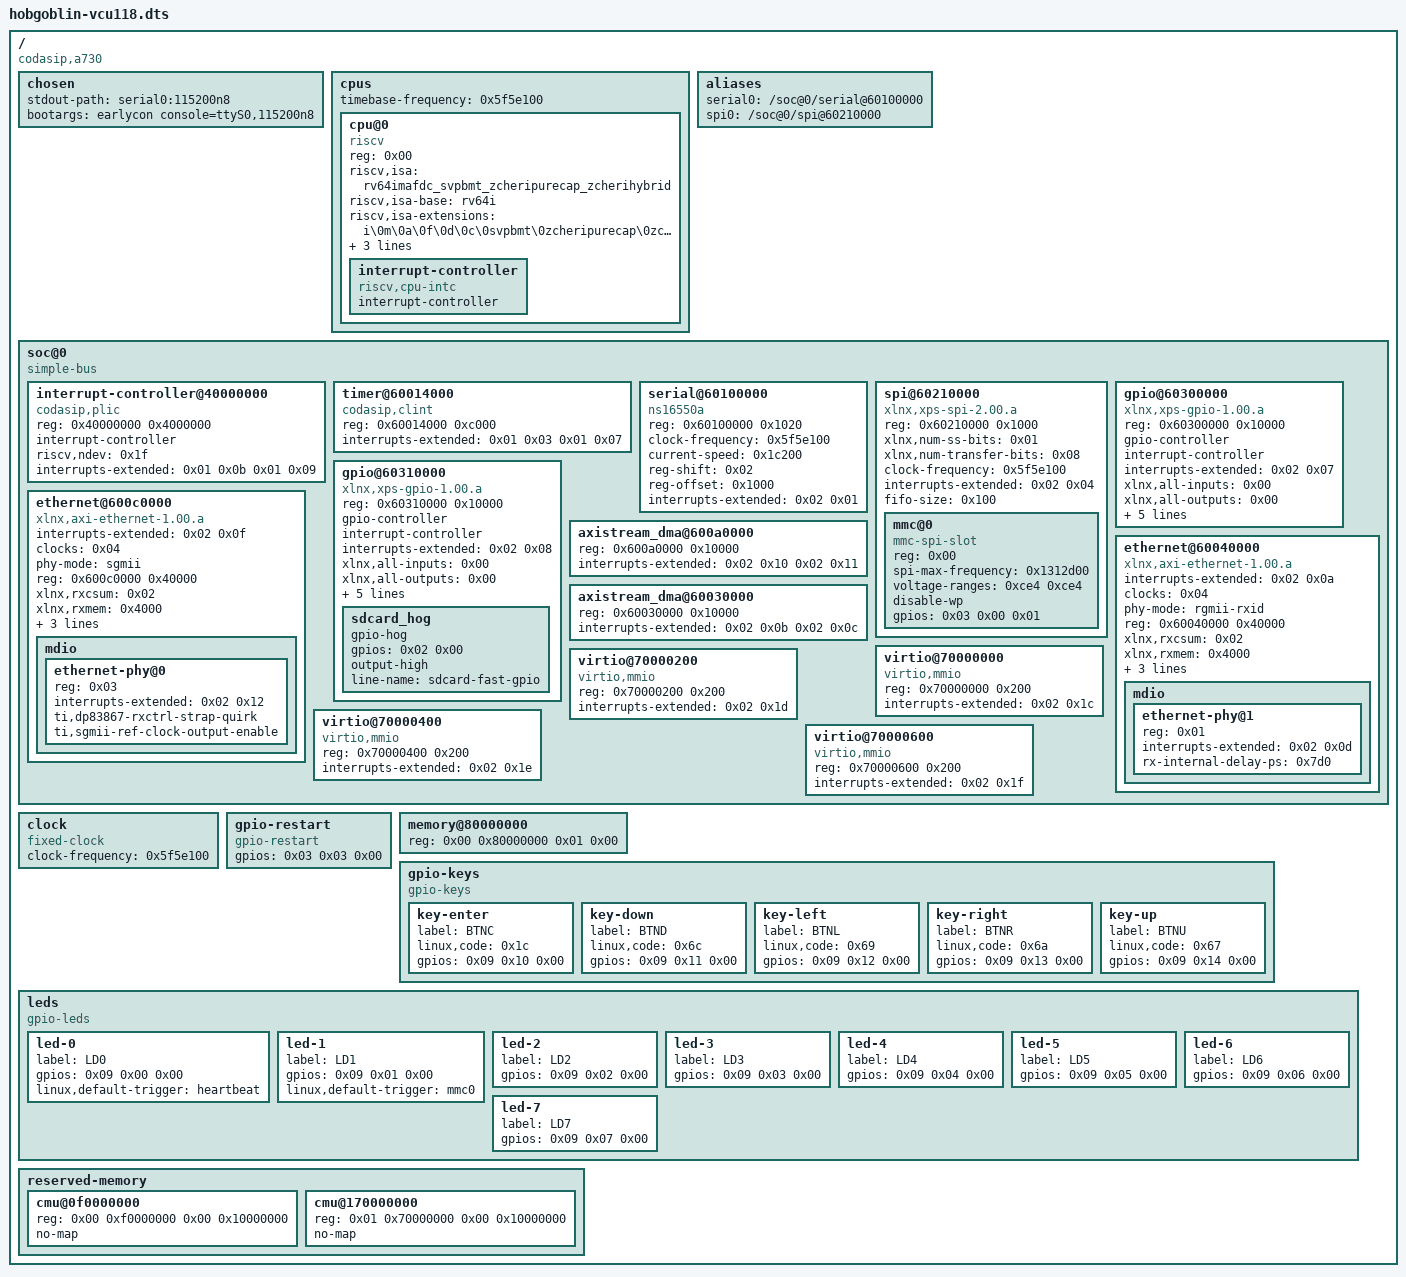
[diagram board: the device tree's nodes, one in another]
/*
 * Copyright (c) 2025, Capabilities Ltd <heshamalmatary@capabilitieslimited.co.uk>
 * This file was derived from Codasip's tools.
 * SPDX-License-Identifier: BSD-3-Clause
 */
/dts-v1/;

/ {
	#address-cells = <0x02>;
	#size-cells = <0x02>;
	compatible = "codasip,a730";

	chosen {
		stdout-path = "serial0:115200n8";
		bootargs = "earlycon console=ttyS0,115200n8";
	};

	cpus {
		#address-cells = <0x01>;
		#size-cells = <0x00>;
		timebase-frequency = <0x5f5e100>;

		cpu@0 {
			compatible = "riscv";
			device_type = "cpu";
			reg = <0x00>;
			riscv,isa = "rv64imafdc_svpbmt_zcheripurecap_zcherihybrid";
			riscv,isa-base = "rv64i";
			riscv,isa-extensions = "i\0m\0a\0f\0d\0c\0svpbmt\0zcheripurecap\0zcherihybrid";
			riscv,cbom-block-size = <0x40>;
			riscv,cboz-block-size = <0x40>;
			mmu-type = "riscv,sv39";
			status = "okay";

			interrupt-controller {
				#interrupt-cells = <0x01>;
				#address-cells = <0x00>;
				compatible = "riscv,cpu-intc";
				interrupt-controller;
				status = "okay";
				phandle = <0x01>;
			};
		};
	};

	aliases {
		serial0 = "/soc@0/serial@60100000";
		spi0 = "/soc@0/spi@60210000";
	};

	soc@0 {
		#address-cells = <0x01>;
		#size-cells = <0x01>;
		compatible = "simple-bus";
		ranges = <0x00 0x00 0x00 0x80000000>;

		interrupt-controller@40000000 {
			compatible = "codasip,plic\0sifive,plic-1.0.0\0riscv,plic0";
			reg = <0x40000000 0x4000000>;
			#address-cells = <0x00>;
			interrupt-controller;
			#interrupt-cells = <0x01>;
			riscv,ndev = <0x1f>;
			interrupts-extended = <0x01 0x0b 0x01 0x09>;
			phandle = <0x02>;
		};

		timer@60014000 {
			compatible = "codasip,clint\0sifive,clint0\0riscv,clint0";
			reg = <0x60014000 0xc000>;
			interrupts-extended = <0x01 0x03 0x01 0x07>;
		};

		serial@60100000 {
			compatible = "ns16550a";
			reg = <0x60100000 0x1020>;
			clock-frequency = <0x5f5e100>;
			current-speed = <0x1c200>;
			reg-shift = <0x02>;
			reg-offset = <0x1000>;
			interrupts-extended = <0x02 0x01>;
		};

		spi@60210000 {
			compatible = "xlnx,xps-spi-2.00.a";
			reg = <0x60210000 0x1000>;
			xlnx,num-ss-bits = <0x01>;
			xlnx,num-transfer-bits = <0x08>;
			clock-frequency = <0x5f5e100>;
			interrupts-extended = <0x02 0x04>;
			fifo-size = <0x100>;
			#address-cells = <0x01>;
			#size-cells = <0x00>;

			mmc@0 {
				compatible = "mmc-spi-slot";
				reg = <0x00>;
				spi-max-frequency = <0x1312d00>;
				voltage-ranges = <0xce4 0xce4>;
				disable-wp;
				gpios = <0x03 0x00 0x01>;
			};
		};

		gpio@60300000 {
			compatible = "xlnx,xps-gpio-1.00.a";
			reg = <0x60300000 0x10000>;
			#gpio-cells = <0x02>;
			#interrupt-cells = <0x02>;
			#address-cells = <0x00>;
			gpio-controller;
			interrupt-controller;
			interrupts-extended = <0x02 0x07>;
			xlnx,all-inputs = <0x00>;
			xlnx,all-outputs = <0x00>;
			xlnx,dout-default = <0x00>;
			xlnx,gpio-width = <0x20>;
			xlnx,interrupt-present = <0x01>;
			xlnx,is-dual = <0x00>;
			xlnx,tri-default = <0xfe>;
			phandle = <0x09>;
		};

		gpio@60310000 {
			compatible = "xlnx,xps-gpio-1.00.a";
			reg = <0x60310000 0x10000>;
			#gpio-cells = <0x02>;
			#interrupt-cells = <0x02>;
			#address-cells = <0x00>;
			gpio-controller;
			interrupt-controller;
			interrupts-extended = <0x02 0x08>;
			xlnx,all-inputs = <0x00>;
			xlnx,all-outputs = <0x00>;
			xlnx,dout-default = <0x00>;
			xlnx,gpio-width = <0x20>;
			xlnx,interrupt-present = <0x01>;
			xlnx,is-dual = <0x00>;
			xlnx,tri-default = <0x01>;
			phandle = <0x03>;

			sdcard_hog {
				gpio-hog;
				gpios = <0x02 0x00>;
				output-high;
				line-name = "sdcard-fast-gpio";
			};
		};

		ethernet@600c0000 {
			compatible = "xlnx,axi-ethernet-1.00.a";
			interrupts-extended = <0x02 0x0f>;
			clock-names = "s_axi_lite_clk";
			clocks = <0x04>;
			phy-mode = "sgmii";
			reg = <0x600c0000 0x40000>;
			xlnx,rxcsum = <0x02>;
			xlnx,rxmem = <0x4000>;
			xlnx,txcsum = <0x02>;
			phy-handle = <0x05>;
			axistream-connected = <0x06>;

			mdio {
				#address-cells = <0x01>;
				#size-cells = <0x00>;

				ethernet-phy@0 {
					device_type = "ethernet-phy";
					reg = <0x03>;
					interrupts-extended = <0x02 0x12>;
					ti,dp83867-rxctrl-strap-quirk;
					ti,sgmii-ref-clock-output-enable;
					phandle = <0x05>;
				};
			};
		};

		axistream_dma@600a0000 {
			reg = <0x600a0000 0x10000>;
			interrupts-extended = <0x02 0x10 0x02 0x11>;
			phandle = <0x06>;
		};

		ethernet@60040000 {
			compatible = "xlnx,axi-ethernet-1.00.a";
			interrupts-extended = <0x02 0x0a>;
			clock-names = "s_axi_lite_clk";
			clocks = <0x04>;
			phy-mode = "rgmii-rxid";
			reg = <0x60040000 0x40000>;
			xlnx,rxcsum = <0x02>;
			xlnx,rxmem = <0x4000>;
			xlnx,txcsum = <0x02>;
			phy-handle = <0x07>;
			axistream-connected = <0x08>;

			mdio {
				#address-cells = <0x01>;
				#size-cells = <0x00>;

				ethernet-phy@1 {
					device_type = "ethernet-phy";
					reg = <0x01>;
					interrupts-extended = <0x02 0x0d>;
					rx-internal-delay-ps = <0x7d0>;
					phandle = <0x07>;
				};
			};
		};

		axistream_dma@60030000 {
			reg = <0x60030000 0x10000>;
			interrupts-extended = <0x02 0x0b 0x02 0x0c>;
			phandle = <0x08>;
		};

		virtio@70000000 {
			compatible = "virtio,mmio";
			reg = <0x70000000 0x200>;
			interrupts-extended = <0x02 0x1c>;
		};

		virtio@70000200 {
			compatible = "virtio,mmio";
			reg = <0x70000200 0x200>;
			interrupts-extended = <0x02 0x1d>;
		};

		virtio@70000400 {
			compatible = "virtio,mmio";
			reg = <0x70000400 0x200>;
			interrupts-extended = <0x02 0x1e>;
		};

		virtio@70000600 {
			compatible = "virtio,mmio";
			reg = <0x70000600 0x200>;
			interrupts-extended = <0x02 0x1f>;
		};
	};

	clock {
		compatible = "fixed-clock";
		#clock-cells = <0x00>;
		clock-frequency = <0x5f5e100>;
		phandle = <0x04>;
	};

	gpio-restart {
		compatible = "gpio-restart";
		gpios = <0x03 0x03 0x00>;
	};

	memory@80000000 {
		device_type = "memory";
		reg = <0x00 0x80000000 0x01 0x00>;
	};

	gpio-keys {
		compatible = "gpio-keys";

		key-enter {
			label = "BTNC";
			linux,code = <0x1c>;
			gpios = <0x09 0x10 0x00>;
		};

		key-down {
			label = "BTND";
			linux,code = <0x6c>;
			gpios = <0x09 0x11 0x00>;
		};

		key-left {
			label = "BTNL";
			linux,code = <0x69>;
			gpios = <0x09 0x12 0x00>;
		};

		key-right {
			label = "BTNR";
			linux,code = <0x6a>;
			gpios = <0x09 0x13 0x00>;
		};

		key-up {
			label = "BTNU";
			linux,code = <0x67>;
			gpios = <0x09 0x14 0x00>;
		};
	};

	leds {
		compatible = "gpio-leds";

		led-0 {
			label = "LD0";
			gpios = <0x09 0x00 0x00>;
			linux,default-trigger = "heartbeat";
		};

		led-1 {
			label = "LD1";
			gpios = <0x09 0x01 0x00>;
			linux,default-trigger = "mmc0";
		};

		led-2 {
			label = "LD2";
			gpios = <0x09 0x02 0x00>;
		};

		led-3 {
			label = "LD3";
			gpios = <0x09 0x03 0x00>;
		};

		led-4 {
			label = "LD4";
			gpios = <0x09 0x04 0x00>;
		};

		led-5 {
			label = "LD5";
			gpios = <0x09 0x05 0x00>;
		};

		led-6 {
			label = "LD6";
			gpios = <0x09 0x06 0x00>;
		};

		led-7 {
			label = "LD7";
			gpios = <0x09 0x07 0x00>;
		};
	};

	reserved-memory {
		#address-cells = <0x02>;
		#size-cells = <0x02>;
		ranges;

		cmu@0f0000000 {
			reg = <0x00 0xf0000000 0x00 0x10000000>;
			no-map;
		};

		cmu@170000000 {
			reg = <0x01 0x70000000 0x00 0x10000000>;
			no-map;
		};
	};
};
